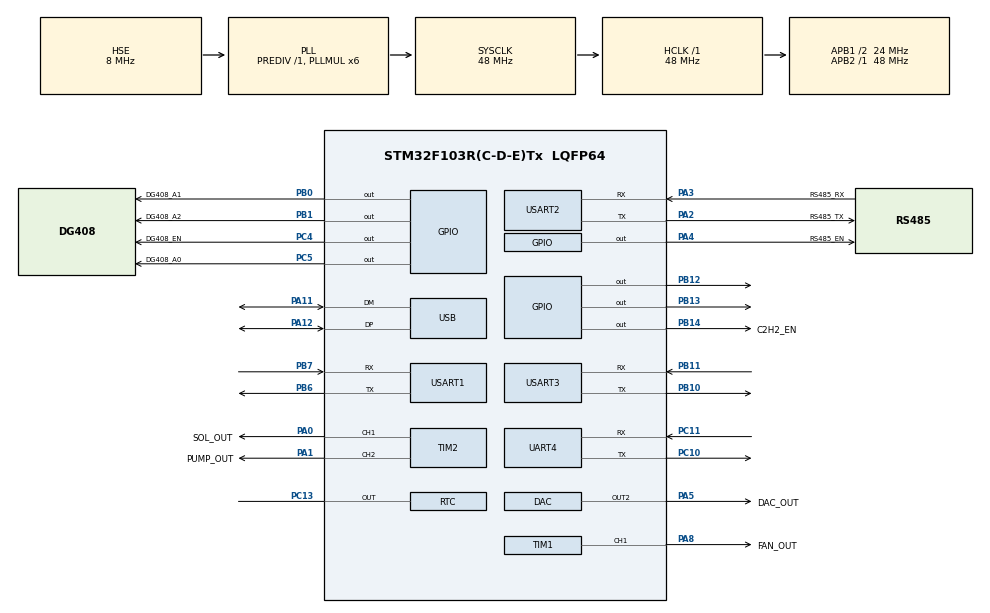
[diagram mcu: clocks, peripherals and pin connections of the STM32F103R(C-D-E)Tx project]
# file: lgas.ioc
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DAC.DAC_OutputBuffer2=DAC_OUTPUTBUFFER_DISABLE
DAC.DAC_Trigger2=DAC_TRIGGER_SOFTWARE
Mcu.Family=STM32F1
Mcu.Name=STM32F103R(C-D-E)Tx
Mcu.Package=LQFP64
NVIC.PriorityGroup=NVIC_PRIORITYGROUP_4
NVIC.UART4_IRQn=true\:0\:0\:false\:false\:true\:true\:true\:true
NVIC.USART1_IRQn=true\:0\:0\:false\:false\:true\:true\:true\:true
NVIC.USART2_IRQn=true\:0\:0\:false\:false\:true\:true\:true\:true
NVIC.USART3_IRQn=true\:0\:0\:false\:false\:true\:true\:true\:true
NVIC.USB_LP_CAN1_RX0_IRQn=true\:0\:0\:false\:false\:true\:false\:true\:true
PA0-WKUP.GPIO_Label=SOL_OUT
PA0-WKUP.Signal=S_TIM2_CH1_ETR
PA1.GPIO_Label=PUMP_OUT
PA1.Signal=S_TIM2_CH2
PA11.Mode=Device
PA11.Signal=USB_DM
PA12.Mode=Device
PA12.Signal=USB_DP
PA13.Mode=Serial_Wire
PA13.Signal=SYS_JTMS-SWDIO
PA14.Mode=Serial_Wire
PA14.Signal=SYS_JTCK-SWCLK
PA2.GPIO_Label=RS485_TX
PA2.Mode=Asynchronous
PA2.Signal=USART2_TX
PA3.GPIO_Label=RS485_RX
PA3.Mode=Asynchronous
PA3.Signal=USART2_RX
PA4.GPIO_Label=RS485_EN
PA4.Signal=GPIO_Output
PA5.GPIO_Label=DAC_OUT
PA5.Signal=COMP_DAC2_group
PA8.GPIO_Label=FAN_OUT
PA8.Signal=S_TIM1_CH1
PB0.GPIO_Label=DG408_A1
PB0.Signal=GPIO_Output
PB1.GPIO_Label=DG408_A2
PB1.Signal=GPIO_Output
PB10.Mode=Asynchronous
PB10.Signal=USART3_TX
PB11.Mode=Asynchronous
PB11.Signal=USART3_RX
PB12.Signal=GPIO_Output
PB13.Signal=GPIO_Output
PB14.GPIO_Label=C2H2_EN
PB14.Signal=GPIO_Output
PB6.Mode=Asynchronous
PB6.Signal=USART1_TX
PB7.Mode=Asynchronous
PB7.Signal=USART1_RX
PC10.Mode=Asynchronous
PC10.Signal=UART4_TX
PC11.Mode=Asynchronous
PC11.Signal=UART4_RX
PC13-TAMPER-RTC.Mode=RTC OUT
PC13-TAMPER-RTC.Signal=RTC_OUT
PC14-OSC32_IN.Mode=LSE-External-Oscillator
PC14-OSC32_IN.Signal=RCC_OSC32_IN
PC15-OSC32_OUT.Mode=LSE-External-Oscillator
PC15-OSC32_OUT.Signal=RCC_OSC32_OUT
PC4.GPIO_Label=DG408_EN
PC4.Signal=GPIO_Output
PC5.GPIO_Label=DG408_A0
PC5.Signal=GPIO_Output
PD0-OSC_IN.Mode=HSE-External-Oscillator
PD0-OSC_IN.Signal=RCC_OSC_IN
PD1-OSC_OUT.Mode=HSE-External-Oscillator
PD1-OSC_OUT.Signal=RCC_OSC_OUT
ProjectManager.HeapSize=0x200
ProjectManager.StackSize=0x400
ProjectManager.TargetToolchain=MDK-ARM V5.32
RCC.ADCPresc=RCC_ADCPCLK2_DIV4
RCC.AHBFreq_Value=48000000
RCC.APB1CLKDivider=RCC_HCLK_DIV2
RCC.APB1Freq_Value=24000000
RCC.APB1TimFreq_Value=48000000
RCC.APB2Freq_Value=48000000
RCC.APB2TimFreq_Value=48000000
RCC.HCLKFreq_Value=48000000
RCC.PLLMUL=RCC_PLL_MUL6
RCC.RTCClockSelection=RCC_RTCCLKSOURCE_LSE
RCC.SYSCLKFreq_VALUE=48000000
RCC.SYSCLKSource=RCC_SYSCLKSOURCE_PLLCLK
RCC.USBFreq_Value=48000000
SH.COMP_DAC2_group.0=DAC_OUT2,DAC_OUT2
SH.S_TIM1_CH1.0=TIM1_CH1,PWM Generation1 CH1
SH.S_TIM2_CH1_ETR.0=TIM2_CH1,PWM Generation1 CH1
SH.S_TIM2_CH2.0=TIM2_CH2,PWM Generation2 CH2
TIM1.Channel-PWM\ Generation1\ CH1=TIM_CHANNEL_1
TIM2.Channel-PWM\ Generation1\ CH1=TIM_CHANNEL_1
TIM2.Channel-PWM\ Generation2\ CH2=TIM_CHANNEL_2
UART4.VirtualMode=Asynchronous
USART1.VirtualMode=VM_ASYNC
USART2.VirtualMode=VM_ASYNC
USART3.VirtualMode=VM_ASYNC
USB_DEVICE.CLASS_NAME_FS=CDC
USB_DEVICE.VirtualMode=Cdc
USB_DEVICE.VirtualModeFS=Cdc_FS
VP_RTC_VS_RTC_Activate.Mode=RTC_Enabled
VP_RTC_VS_RTC_Calendar.Mode=RTC_Calendar
VP_TIM1_VS_ClockSourceINT.Mode=Internal
VP_TIM2_VS_ClockSourceINT.Mode=Internal
VP_TIM2_VS_ClockSourceITR.Mode=TriggerSource_ITR0
VP_USB_DEVICE_VS_USB_DEVICE_CDC_FS.Mode=CDC_FS
board=custom

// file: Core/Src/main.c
/* USER CODE BEGIN Header */
/**
  ******************************************************************************
  * @file           : main.c
  * @brief          : Main program body
  ******************************************************************************
  * @attention
  *
  * Copyright (c) 2026 STMicroelectronics.
  * All rights reserved.
  *
  * This software is licensed under terms that can be found in the LICENSE file
  * in the root directory of this software component.
  * If no LICENSE file comes with this software, it is provided AS-IS.
  *
  ******************************************************************************
  */
/* USER CODE END Header */
#include "main.h"
#include "usb_device.h"
#include "usbd_cdc_if.h"
#include "rtc.h"
#include "fan.h"
#include "pump.h"
#include "uart.h"
#include "modbus_master.h"
#include "usb_task.h"
#include "start_task.h"
#include "DAC.h"
#include "dgusii.h"
#include "HMI_task.h"
#include "modbus_master_h2.h"
#include "start_task.h"
#include "hmi_text_gbk.h"
#include "app_tasks.h"
#include "fault_monitor.h"
#include <string.h>
#include "solenoid.h"

DAC_HandleTypeDef hdac;

RTC_HandleTypeDef hrtc;

TIM_HandleTypeDef htim1;
TIM_HandleTypeDef htim2;

UART_HandleTypeDef huart4;
UART_HandleTypeDef huart1;
UART_HandleTypeDef huart2;
UART_HandleTypeDef huart3;

void SystemClock_Config(void);
static void MX_GPIO_Init(void);
static void MX_DAC_Init(void);
static void MX_RTC_Init(void);
static void MX_TIM1_Init(void);
static void MX_TIM2_Init(void);
static void MX_UART4_Init(void);
static void MX_USART1_UART_Init(void);
static void MX_USART2_UART_Init(void);
static void MX_USART3_UART_Init(void);

int main(void)
{

  /* USER CODE BEGIN 1 */
  static uint32_t ontime_start = 0;
  uint8_t sys_status = STARTUP  ;
	uint8_t fail_n = 0U, sys_fail = 0U;
	char sys_fail_buf[64];
  /* USER CODE END 1 */

  /* MCU Configuration--------------------------------------------------------*/

  /* Reset of all peripherals, Initializes the Flash interface and the Systick. */
  HAL_Init();

  /* Configure the system clock */
  SystemClock_Config();

  /* Initialize all configured peripherals */
  MX_GPIO_Init();
  MX_DAC_Init();

#if 0
  MX_RTC_Init();
#else
  /* USB bring-up on empty board: skip RTC/LSE path temporarily. */
#endif
  MX_TIM1_Init();
  MX_TIM2_Init();
  MX_UART4_Init();
  MX_USART1_UART_Init();
  MX_USART2_UART_Init();
  MX_USART3_UART_Init();
  MX_USB_DEVICE_Init();
  modbus_master_init();
  modbus_master_h2_init();
  /* USER CODE BEGIN 2 */
	uart_startReceiveIT(UART_PORT_UART4);
#if 1
  rtc_init();
#else
  /* USB bring-up on empty board: skip RTC/LSE path temporarily. */
#endif
  if (DAC_OutputInit() != 0U)
  {
      Error_Handler();
  }
  pump_init();
  fan_init();
  dgusii_init(dgusii_HMI_task,NULL);
  //pump_set_strength(70);
  //app_mem_init();
  //loop_profiler_init(1000U);
  if(usb_task_init()!=0)
  {
      Error_Handler();
  }
	HMI_Powerstatus(TRUE);
  PowerOn_setTime(0);
  ontime_start = PowerOn_getTime();
  HAL_Delay(1000);
	uart_sendData(DGUSII_UART_PORT, HMI_TEXT_INITING_GBK, HMI_TEXT_INITING_GBK_LEN, DGUSII_TX_TIMEOUT_MS);
  HAL_Delay(1000);
  uart_sendData(DGUSII_UART_PORT, HMI_SCREEN_LIGHT, HMIHMI_SCREEN_LIGHT_LEN, DGUSII_TX_TIMEOUT_MS);

  /* Infinite loop */
  while (1)
  {
    switch (sys_status)
    {
    case STARTUP:
      fan_set_speed(100);
	    HAL_Delay(100);
      uart_sendData(DGUSII_UART_PORT, HMI_CLOSE_TOUCH, HMI_CLOSE_TOUCH_LEN, DGUSII_TX_TIMEOUT_MS);
      HAL_Delay(100);
      if ((sys_fail=start_task_run()) == 0U)
      {
        sys_status = WARNUP;
        uart_sendData(DGUSII_UART_PORT, HMI_TEXT_PREHEAT_GBK, HMI_TEXT_PREHEAT_GBK_LEN, DGUSII_TX_TIMEOUT_MS);
      }
      else
      {
        uint8_t *opentofail = (uint8_t*)HMI_TEXT_INIT_ERR_ID_GBK;
        static const uint8_t hex_digit[] = "0123456789ABCDEF";
        opentofail[HMI_TEXT_INIT_ERR_ID_GBK_LEN-2] = hex_digit[(sys_fail >> 4) & 0x0FU];
        opentofail[HMI_TEXT_INIT_ERR_ID_GBK_LEN-1] = hex_digit[sys_fail & 0x0FU];
        uart_sendData(DGUSII_UART_PORT, opentofail, HMI_TEXT_INIT_ERR_ID_GBK_LEN, DGUSII_TX_TIMEOUT_MS);
				sprintf(sys_fail_buf,"init fail=%x,fail num=%d\r\n",sys_fail,fail_n);
				usb_cdc_send_packet((uint8_t *)sys_fail_buf, (uint16_t)strlen(sys_fail_buf));
        #ifdef HW_VERIGY
				fail_n += 1;
        sys_status = STOP;
        #else

        sys_status = WARNUP;
        #endif
      }
      break;

    case WARNUP:
      if(PowerOn_getTime()-ontime_start<=WARNMIN*1000)
        break;
      if((sys_fail=start_task_readbase()) == 0U)
      {
        sys_status = RUNING;
      }else{
				uint8_t *opentofail = (uint8_t*)HMI_TEXT_INIT_ERR_ID_GBK;
        static const uint8_t hex_digit[] = "0123456789ABCDEF";
        opentofail[HMI_TEXT_INIT_ERR_ID_GBK_LEN-2] = hex_digit[(sys_fail >> 4) & 0x0FU];
        opentofail[HMI_TEXT_INIT_ERR_ID_GBK_LEN-1] = hex_digit[sys_fail & 0x0FU];
        uart_sendData(DGUSII_UART_PORT, opentofail, HMI_TEXT_INIT_ERR_ID_GBK_LEN, DGUSII_TX_TIMEOUT_MS);
				sprintf(sys_fail_buf,"init fail=%x,fail num=%d\r\n",sys_fail,fail_n);
				usb_cdc_send_packet((uint8_t *)sys_fail_buf, (uint16_t)strlen(sys_fail_buf));
        #ifdef HW_VERIGY
				fail_n += 1;
        sys_status = STOP;
        #else

        sys_status = WARNUP;
        #endif
			}
			uart_sendData(DGUSII_UART_PORT, HMI_OPEN_TOUCH, HMI_OPEN_TOUCH_LEN, DGUSII_TX_TIMEOUT_MS);
      HAL_Delay(100);
      uart_sendData(DGUSII_UART_PORT, HMI_INTO_MENU, HMI_INTO_MENU_LEN, DGUSII_TX_TIMEOUT_MS);
			HAL_Delay(100);
      solenoid_set_duty(100);
    break;
    case RUNING:
      //loop_profiler_begin();
      app_tasks_run_running();
      //loop_profiler_end();
      break;

    case STOP:
      app_tasks_run_stop();
      break;

    default:
      break;

    }

  }
}

void SystemClock_Config(void)
{
  RCC_OscInitTypeDef RCC_OscInitStruct = {0};
  RCC_ClkInitTypeDef RCC_ClkInitStruct = {0};
  RCC_PeriphCLKInitTypeDef PeriphClkInit = {0};

  /** Initializes the RCC Oscillators according to the specified parameters
  * in the RCC_OscInitTypeDef structure.
  */
  #if 0
  RCC_OscInitStruct.OscillatorType = RCC_OSCILLATORTYPE_HSE|RCC_OSCILLATORTYPE_LSE;
  RCC_OscInitStruct.HSEState = RCC_HSE_ON;
  RCC_OscInitStruct.HSEPredivValue = RCC_HSE_PREDIV_DIV1;
  RCC_OscInitStruct.LSEState = RCC_LSE_ON;
  RCC_OscInitStruct.HSIState = RCC_HSI_ON;
  RCC_OscInitStruct.PLL.PLLState = RCC_PLL_ON;
  RCC_OscInitStruct.PLL.PLLSource = RCC_PLLSOURCE_HSE;
  RCC_OscInitStruct.PLL.PLLMUL = RCC_PLL_MUL6;
  #else
  RCC_OscInitStruct.OscillatorType = RCC_OSCILLATORTYPE_HSE;
  RCC_OscInitStruct.HSEState = RCC_HSE_ON;
  RCC_OscInitStruct.HSEPredivValue = RCC_HSE_PREDIV_DIV1;
  RCC_OscInitStruct.HSIState = RCC_HSI_ON;
  RCC_OscInitStruct.PLL.PLLState = RCC_PLL_ON;
  RCC_OscInitStruct.PLL.PLLSource = RCC_PLLSOURCE_HSE;
  RCC_OscInitStruct.PLL.PLLMUL = RCC_PLL_MUL6;
  #endif
  if (HAL_RCC_OscConfig(&RCC_OscInitStruct) != HAL_OK)
  {
    Error_Handler();
  }

  /** Initializes the CPU, AHB and APB buses clocks
  */
  RCC_ClkInitStruct.ClockType = RCC_CLOCKTYPE_HCLK|RCC_CLOCKTYPE_SYSCLK
                              |RCC_CLOCKTYPE_PCLK1|RCC_CLOCKTYPE_PCLK2;
  RCC_ClkInitStruct.SYSCLKSource = RCC_SYSCLKSOURCE_PLLCLK;
  RCC_ClkInitStruct.AHBCLKDivider = RCC_SYSCLK_DIV1;
  RCC_ClkInitStruct.APB1CLKDivider = RCC_HCLK_DIV2;
  RCC_ClkInitStruct.APB2CLKDivider = RCC_HCLK_DIV1;

  if (HAL_RCC_ClockConfig(&RCC_ClkInitStruct, FLASH_LATENCY_1) != HAL_OK)
  {
    Error_Handler();
  }
  #if 0
  PeriphClkInit.PeriphClockSelection = RCC_PERIPHCLK_RTC|RCC_PERIPHCLK_USB;
  PeriphClkInit.RTCClockSelection = RCC_RTCCLKSOURCE_LSE;
  PeriphClkInit.UsbClockSelection = RCC_USBCLKSOURCE_PLL;
  #else
  PeriphClkInit.PeriphClockSelection = RCC_PERIPHCLK_USB;
  PeriphClkInit.UsbClockSelection = RCC_USBCLKSOURCE_PLL;
  #endif
  if (HAL_RCCEx_PeriphCLKConfig(&PeriphClkInit) != HAL_OK)
  {
    Error_Handler();
  }
}

static void MX_DAC_Init(void)
{

  DAC_ChannelConfTypeDef sConfig = {0};

  /** DAC Initialization
  */
  hdac.Instance = DAC;
  if (HAL_DAC_Init(&hdac) != HAL_OK)
  {
    Error_Handler();
  }

  /** DAC channel OUT2 config
  */
  sConfig.DAC_Trigger = DAC_TRIGGER_NONE;
  sConfig.DAC_OutputBuffer = DAC_OUTPUTBUFFER_DISABLE;
  if (HAL_DAC_ConfigChannel(&hdac, &sConfig, DAC_CHANNEL_2) != HAL_OK)
  {
    Error_Handler();
  }

}

static void MX_RTC_Init(void)
{
  /** Initialize RTC Only
  */
  hrtc.Instance = RTC;
  hrtc.Init.AsynchPrediv = RTC_AUTO_1_SECOND;
  hrtc.Init.OutPut = RTC_OUTPUTSOURCE_ALARM;
  if (HAL_RTC_Init(&hrtc) != HAL_OK)
  {
    Error_Handler();
  }

}

static void MX_TIM1_Init(void)
{

  TIM_ClockConfigTypeDef sClockSourceConfig = {0};
  TIM_MasterConfigTypeDef sMasterConfig = {0};
  TIM_OC_InitTypeDef sConfigOC = {0};
  TIM_BreakDeadTimeConfigTypeDef sBreakDeadTimeConfig = {0};

  htim1.Instance = TIM1;
  htim1.Init.Prescaler = 0;
  htim1.Init.CounterMode = TIM_COUNTERMODE_UP;
  htim1.Init.Period = 65535;
  htim1.Init.ClockDivision = TIM_CLOCKDIVISION_DIV1;
  htim1.Init.RepetitionCounter = 0;
  htim1.Init.AutoReloadPreload = TIM_AUTORELOAD_PRELOAD_DISABLE;
  if (HAL_TIM_Base_Init(&htim1) != HAL_OK)
  {
    Error_Handler();
  }
  sClockSourceConfig.ClockSource = TIM_CLOCKSOURCE_INTERNAL;
  if (HAL_TIM_ConfigClockSource(&htim1, &sClockSourceConfig) != HAL_OK)
  {
    Error_Handler();
  }
  if (HAL_TIM_PWM_Init(&htim1) != HAL_OK)
  {
    Error_Handler();
  }
  sMasterConfig.MasterOutputTrigger = TIM_TRGO_RESET;
  sMasterConfig.MasterSlaveMode = TIM_MASTERSLAVEMODE_DISABLE;
  if (HAL_TIMEx_MasterConfigSynchronization(&htim1, &sMasterConfig) != HAL_OK)
  {
    Error_Handler();
  }
  sConfigOC.OCMode = TIM_OCMODE_PWM1;
  sConfigOC.Pulse = 0;
  sConfigOC.OCPolarity = TIM_OCPOLARITY_HIGH;
  sConfigOC.OCNPolarity = TIM_OCNPOLARITY_HIGH;
  sConfigOC.OCFastMode = TIM_OCFAST_DISABLE;
  sConfigOC.OCIdleState = TIM_OCIDLESTATE_RESET;
  sConfigOC.OCNIdleState = TIM_OCNIDLESTATE_RESET;
  if (HAL_TIM_PWM_ConfigChannel(&htim1, &sConfigOC, TIM_CHANNEL_1) != HAL_OK)
  {
    Error_Handler();
  }
  sBreakDeadTimeConfig.OffStateRunMode = TIM_OSSR_DISABLE;
  sBreakDeadTimeConfig.OffStateIDLEMode = TIM_OSSI_DISABLE;
  sBreakDeadTimeConfig.LockLevel = TIM_LOCKLEVEL_OFF;
  sBreakDeadTimeConfig.DeadTime = 0;
  sBreakDeadTimeConfig.BreakState = TIM_BREAK_DISABLE;
  sBreakDeadTimeConfig.BreakPolarity = TIM_BREAKPOLARITY_HIGH;
  sBreakDeadTimeConfig.AutomaticOutput = TIM_AUTOMATICOUTPUT_DISABLE;
  if (HAL_TIMEx_ConfigBreakDeadTime(&htim1, &sBreakDeadTimeConfig) != HAL_OK)
  {
    Error_Handler();
  }
  HAL_TIM_MspPostInit(&htim1);

}

static void MX_TIM2_Init(void)
{

  TIM_ClockConfigTypeDef sClockSourceConfig = {0};
  TIM_SlaveConfigTypeDef sSlaveConfig = {0};
  TIM_MasterConfigTypeDef sMasterConfig = {0};
  TIM_OC_InitTypeDef sConfigOC = {0};

  htim2.Instance = TIM2;
  htim2.Init.Prescaler = 0;
  htim2.Init.CounterMode = TIM_COUNTERMODE_UP;
  htim2.Init.Period = 65535;
  htim2.Init.ClockDivision = TIM_CLOCKDIVISION_DIV1;
  htim2.Init.AutoReloadPreload = TIM_AUTORELOAD_PRELOAD_DISABLE;
  if (HAL_TIM_Base_Init(&htim2) != HAL_OK)
  {
    Error_Handler();
  }
  sClockSourceConfig.ClockSource = TIM_CLOCKSOURCE_INTERNAL;
  if (HAL_TIM_ConfigClockSource(&htim2, &sClockSourceConfig) != HAL_OK)
  {
    Error_Handler();
  }
  if (HAL_TIM_PWM_Init(&htim2) != HAL_OK)
  {
    Error_Handler();
  }
  sSlaveConfig.SlaveMode = TIM_SLAVEMODE_DISABLE;
  sSlaveConfig.InputTrigger = TIM_TS_ITR0;
  if (HAL_TIM_SlaveConfigSynchro(&htim2, &sSlaveConfig) != HAL_OK)
  {
    Error_Handler();
  }
  sMasterConfig.MasterOutputTrigger = TIM_TRGO_RESET;
  sMasterConfig.MasterSlaveMode = TIM_MASTERSLAVEMODE_DISABLE;
  if (HAL_TIMEx_MasterConfigSynchronization(&htim2, &sMasterConfig) != HAL_OK)
  {
    Error_Handler();
  }
  sConfigOC.OCMode = TIM_OCMODE_PWM1;
  sConfigOC.Pulse = 0;
  sConfigOC.OCPolarity = TIM_OCPOLARITY_HIGH;
  sConfigOC.OCFastMode = TIM_OCFAST_DISABLE;
  if (HAL_TIM_PWM_ConfigChannel(&htim2, &sConfigOC, TIM_CHANNEL_1) != HAL_OK)
  {
    Error_Handler();
  }
  if (HAL_TIM_PWM_ConfigChannel(&htim2, &sConfigOC, TIM_CHANNEL_2) != HAL_OK)
  {
    Error_Handler();
  }
  HAL_TIM_MspPostInit(&htim2);

}

static void MX_UART4_Init(void)
{

  huart4.Instance = UART4;
  huart4.Init.BaudRate = 9600;
  huart4.Init.WordLength = UART_WORDLENGTH_8B;
  huart4.Init.StopBits = UART_STOPBITS_1;
  huart4.Init.Parity = UART_PARITY_NONE;
  huart4.Init.Mode = UART_MODE_TX_RX;
  huart4.Init.HwFlowCtl = UART_HWCONTROL_NONE;
  huart4.Init.OverSampling = UART_OVERSAMPLING_16;
  if (HAL_UART_Init(&huart4) != HAL_OK)
  {
    Error_Handler();
  }

}

static void MX_USART1_UART_Init(void)
{

  huart1.Instance = USART1;
  huart1.Init.BaudRate = 19200;
  huart1.Init.WordLength = UART_WORDLENGTH_8B;
  huart1.Init.StopBits = UART_STOPBITS_1;
  huart1.Init.Parity = UART_PARITY_NONE;
  huart1.Init.Mode = UART_MODE_TX_RX;
  huart1.Init.HwFlowCtl = UART_HWCONTROL_NONE;
  huart1.Init.OverSampling = UART_OVERSAMPLING_16;
  if (HAL_UART_Init(&huart1) != HAL_OK)
  {
    Error_Handler();
  }

}

static void MX_USART2_UART_Init(void)
{

  huart2.Instance = USART2;
  huart2.Init.BaudRate = 115200;
  huart2.Init.WordLength = UART_WORDLENGTH_8B;
  huart2.Init.StopBits = UART_STOPBITS_1;
  huart2.Init.Parity = UART_PARITY_NONE;
  huart2.Init.Mode = UART_MODE_TX_RX;
  huart2.Init.HwFlowCtl = UART_HWCONTROL_NONE;
  huart2.Init.OverSampling = UART_OVERSAMPLING_16;
  if (HAL_UART_Init(&huart2) != HAL_OK)
  {
    Error_Handler();
  }

}

static void MX_USART3_UART_Init(void)
{

  huart3.Instance = USART3;
  huart3.Init.BaudRate = 115200;
  huart3.Init.WordLength = UART_WORDLENGTH_8B;
  huart3.Init.StopBits = UART_STOPBITS_1;
  huart3.Init.Parity = UART_PARITY_NONE;
  huart3.Init.Mode = UART_MODE_TX_RX;
  huart3.Init.HwFlowCtl = UART_HWCONTROL_NONE;
  huart3.Init.OverSampling = UART_OVERSAMPLING_16;
  if (HAL_UART_Init(&huart3) != HAL_OK)
  {
    Error_Handler();
  }

}

static void MX_GPIO_Init(void)
{
  GPIO_InitTypeDef GPIO_InitStruct = {0};

  /* GPIO Ports Clock Enable */
  __HAL_RCC_GPIOC_CLK_ENABLE();
  __HAL_RCC_GPIOD_CLK_ENABLE();
  __HAL_RCC_GPIOA_CLK_ENABLE();
  __HAL_RCC_GPIOB_CLK_ENABLE();

  /*Configure GPIO pin Output Level */
  HAL_GPIO_WritePin(RS485_EN_GPIO_Port, RS485_EN_Pin, GPIO_PIN_RESET);

  /*Configure GPIO pin Output Level */
  HAL_GPIO_WritePin(GPIOC, DG408_EN_Pin|DG408_A0_Pin, GPIO_PIN_RESET);

  /*Configure GPIO pin Output Level */
  HAL_GPIO_WritePin(GPIOB, DG408_A1_Pin|DG408_A2_Pin|GPIO_PIN_12|GPIO_PIN_13
                          |C2H2_EN_Pin|HMI_EN_Pin|GPIO_PIN_12, GPIO_PIN_RESET);

  /*Configure GPIO pin : RS485_EN_Pin */
  GPIO_InitStruct.Pin = RS485_EN_Pin;
  GPIO_InitStruct.Mode = GPIO_MODE_OUTPUT_PP;
  GPIO_InitStruct.Pull = GPIO_NOPULL;
  GPIO_InitStruct.Speed = GPIO_SPEED_FREQ_LOW;
  HAL_GPIO_Init(RS485_EN_GPIO_Port, &GPIO_InitStruct);

  /*Configure GPIO pins : DG408_EN_Pin DG408_A0_Pin */
  GPIO_InitStruct.Pin = DG408_EN_Pin|DG408_A0_Pin;
  GPIO_InitStruct.Mode = GPIO_MODE_OUTPUT_PP;
  GPIO_InitStruct.Pull = GPIO_NOPULL;
  GPIO_InitStruct.Speed = GPIO_SPEED_FREQ_LOW;
  HAL_GPIO_Init(GPIOC, &GPIO_InitStruct);

  /*Configure GPIO pins : DG408_A1_Pin DG408_A2_Pin PB12 PB13
                           C2H2_EN_Pin */
  GPIO_InitStruct.Pin = DG408_A1_Pin|DG408_A2_Pin|GPIO_PIN_12|GPIO_PIN_13|GPIO_PIN_12
                          |C2H2_EN_Pin|HMI_EN_Pin;
  GPIO_InitStruct.Mode = GPIO_MODE_OUTPUT_PP;
  GPIO_InitStruct.Pull = GPIO_NOPULL;
  GPIO_InitStruct.Speed = GPIO_SPEED_FREQ_LOW;
  HAL_GPIO_Init(GPIOB, &GPIO_InitStruct);

}

void Error_Handler(void)
{
  /* USER CODE BEGIN Error_Handler_Debug */
  /* User can add his own implementation to report the HAL error return state */
  __disable_irq();
  fault_monitor_capture(FAULT_MONITOR_EVT_ERROR, 0U, 0U);
  while (1)
  {
  }
  /* USER CODE END Error_Handler_Debug */
}
